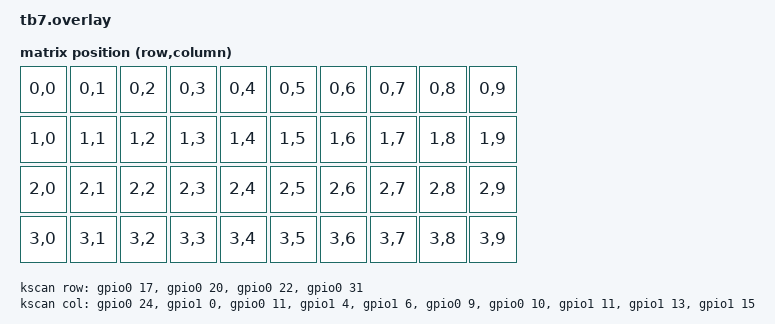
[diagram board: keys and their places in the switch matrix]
// This file was generated from a template. Edit it to match your keyboard.
// See https://zmk.dev/docs/development/hardware-integration/new-shield for more
// instructions.

#include <dt-bindings/zmk/matrix_transform.h>
// #include <dt-bindings/zmk/sensors.h>

#include "tb7-layouts.dtsi"

#include <dt-bindings/zmk/outputs.h>
#include <dt-bindings/interrupt-controller/arm-gic.h>
#include <dt-bindings/pinctrl/nrf-pinctrl.h>  

// &uart1 { status = "okay"; };


/ {
    chosen {
        zmk,physical-layout = &default_layout;
        zephyr,display = &oled_128x64;
        //        zmk,studio-rpc-uart = &uart1;
    };


    kscan: kscan {
        // If the hardware does not use a switch matrix, change this to the
        // appropriate driver and update the properties below to match.
        // See https://zmk.dev/docs/config/kscan for supported key scan drivers.
        compatible = "zmk,kscan-gpio-matrix";
        // Set this to "col2row" or "row2col" to match the hardware. If using
        // "row2col", change the col-gpios to (GPIO_ACTIVE_HIGH | GPIO_PULL_DOWN)
        // and the row-gpios to GPIO_ACTIVE_HIGH.
        diode-direction = "col2row";
        wakeup-source;

        // Replace these comments with the GPIO pins in the matrix.
        // See https://zmk.dev/docs/development/hardware-integration/new-shield#shield-overlays
        // gpio1 0 사망했거나, 번호 착오로 보인다.


// &gpio1 06  허용 안됨. &gpio1 6 으로 명시 해야함.
 
        col-gpios
            = <&gpio0 24 GPIO_ACTIVE_HIGH>
            , <&gpio1 0 GPIO_ACTIVE_HIGH>
            , <&gpio0 11 GPIO_ACTIVE_HIGH>
            , <&gpio1 4 GPIO_ACTIVE_HIGH>
            , <&gpio1 6 GPIO_ACTIVE_HIGH>
            , <&gpio0 9 GPIO_ACTIVE_HIGH>
            , <&gpio0 10 GPIO_ACTIVE_HIGH>
            , <&gpio1 11 GPIO_ACTIVE_HIGH>
            , <&gpio1 13 GPIO_ACTIVE_HIGH>
            , <&gpio1 15 GPIO_ACTIVE_HIGH>
            ;

        row-gpios
            = <&gpio0 17 (GPIO_ACTIVE_HIGH | GPIO_PULL_DOWN)>
            , <&gpio0 20 (GPIO_ACTIVE_HIGH | GPIO_PULL_DOWN)>
            , <&gpio0 22 (GPIO_ACTIVE_HIGH | GPIO_PULL_DOWN)>
            , <&gpio0 31 (GPIO_ACTIVE_HIGH | GPIO_PULL_DOWN)>
            ;

    };

    default_transform: default_transform {
        // See https://zmk.dev/docs/development/hardware-integration/new-shield#matrix-transform
        // for how to configure this
        compatible = "zmk,matrix-transform";
        columns = <10>;
        rows = <4>;

        map = <
            RC(0, 0) RC(0, 1) RC(0, 2) RC(0, 3) RC(0, 4) RC(0, 5) RC(0, 6) RC(0, 7) RC(0, 8) RC(0, 9)
            RC(1, 0) RC(1, 1) RC(1, 2) RC(1, 3) RC(1, 4) RC(1, 5) RC(1, 6) RC(1, 7) RC(1, 8) RC(1, 9)
            RC(2, 0) RC(2, 1) RC(2, 2) RC(2, 3) RC(2, 4) RC(2, 5) RC(2, 6) RC(2, 7) RC(2, 8) RC(2, 9)
            RC(3, 0) RC(3, 1) RC(3, 2) RC(3, 3) RC(3, 4) RC(3, 5) RC(3, 6) RC(3, 7) RC(3, 8) RC(3, 9)
        >;
    };

    
    /* 1. 하드웨어 핀 정의 
    left_encoder: encoder_left {
        compatible = "alps,ec11";
        label = "LEFT_ENCODER";
        a-gpios = <&gpio1 0  (GPIO_ACTIVE_LOW | GPIO_PULL_UP)>;
        b-gpios = <&gpio0 11 (GPIO_ACTIVE_LOW | GPIO_PULL_UP)>;
        steps = <80>; // 엔코더 사양에 맞춰 조절 (보통 80 또는 72)
        resolution = <4>;
        status = "okay";
    };

    right_encoder: encoder_right {
        compatible = "alps,ec11";
        label = "RIGHT_ENCODER";
        a-gpios = <&gpio1 4 (GPIO_ACTIVE_LOW | GPIO_PULL_UP)>;
        b-gpios = <&gpio0 6 (GPIO_ACTIVE_LOW | GPIO_PULL_UP)>;
        steps = <80>; // 엔코더 사양에 맞춰 조절 (보통 80 또는 72)
        resolution = <4>;
        status = "okay";
    };
*/

            /* 2. 센서 등록 */
//    sensors {
//        compatible = "zmk,keymap-sensors";
//        sensors = <&left_encoder &right_encoder>;
//        triggers-per-rotation = <20>; // 한 바퀴 회전 시 인식 횟수
//    };


};


// 디스플레이 사용을 위한 I2C 핀 설정
// SDA : P0.8
// SCL : P0.6

&pinctrl {
    i2c0_default: i2c0_default {
        group1 {
            psels = <NRF_PSEL(TWIM_SDA, 0, 8)>,
                    <NRF_PSEL(TWIM_SCL, 0, 6)>;
            bias-pull-up;
        };
    };

    i2c0_sleep: i2c0_sleep {
        group1 {
            psels = <NRF_PSEL(TWIM_SDA, 0, 8)>,
                    <NRF_PSEL(TWIM_SCL, 0, 6)>;
            low-power-enable;
        };
    };
};

&i2c0 {
    status = "okay";
    pinctrl-0 = <&i2c0_default>;
    pinctrl-1 = <&i2c0_sleep>;
    pinctrl-names = "default", "sleep";

        oled_128x64: ssd1306@3c {
        compatible = "solomon,ssd1306fb";
        reg = <0x3c>;
        width = <128>;
        height = <64>;
        segment-offset = <0>;
        page-offset = <0>;
        display-offset = <0>;
        multiplex-ratio = <63>;    // 128x64 디스플레이의 경우 63으로 설정    
        segment-remap;
        com-invdir;
//         com-sequential;      // 128x64에서는 미사용. 128x32에서만 사용.
        inversion-on;
        prechargep = <0x22>;
    };


};



/* nice!nano(nRF52840)에서 UART0 비활성화 */
// &uart0 {status = "disabled";};

// spi3 핀 할당 for 74HC595 시프트 레지스터
// CLOCK        : P0.17
// MOSI(DATA)   : P0.20
// LATCH        : P0.22 (GPIO로 제어)


/*
 &pinctrl {
    spi3_default: spi3_default {
        group1 {
            psels = <NRF_PSEL(SPIM_SCK, 0, 6)>,
                    <NRF_PSEL(SPIM_MOSI, 0, 8)>;
                        };
    };

    spi3_sleep: spi3_sleep {
        group1 {
            psels = <NRF_PSEL(SPIM_SCK, 0, 6)>,
                    <NRF_PSEL(SPIM_MOSI, 0, 8)>;
                    low-power-enable;
        };
    };
};
*/


/*
&spi3 {
	compatible = "nordic,nrf-spim";
	status = "okay";
	pinctrl-0 = <&spi3_default>;
	pinctrl-1 = <&spi3_sleep>;
	pinctrl-names = "default", "sleep";

    //wakeup-source; 
    // Pin 0.22 for CS (Chip Select), active low
    cs-gpios = <&gpio0 22 GPIO_ACTIVE_LOW>;

    sr0: 595@0 {
		compatible = "zmk,gpio-595";
		status = "okay";
		gpio-controller;
		spi-max-frequency = <2000000>;
		reg = <0>;
		label = "74HC595";
		#gpio-cells = <2>;
		ngpios = <8>;
	};
};




&spi3 {
    status = "okay";
    compatible = "nordic,nrf-spim";
    cs-gpios = <&gpio0 22 GPIO_ACTIVE_LOW>;
    pinctrl-0 = <&spi3_default>;
    pinctrl-1 = <&spi3_sleep>;
    pinctrl-names = "default", "sleep";

    shifter: 595@0 {
        compatible = "zmk,gpio-595";
        status = "okay";
        gpio-controller;
        spi-max-frequency = <200000>;
        reg = <0>;
        #gpio-cells = <2>;
        ngpios = <8>;
    };
};



&xiao_spi {
	status = "okay";
	cs-gpios = <&xiao_d 9 GPIO_ACTIVE_LOW>;
	shifter: 595@0 {
		compatible = "zmk,gpio-595";
		status = "okay";
		gpio-controller;
		spi-max-frequency = <200000>;
		reg = <0>;
		#gpio-cells = <2>;
		ngpios = <8>;
	};
};

*/
